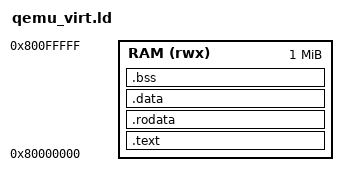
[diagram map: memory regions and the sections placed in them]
/* Linker script of programs for QEMU virt machine: RAM at 0x80000000,
 * QEMU starts at the beginning of RAM, so .text.start (_start of crt0.S) is first.
 */
OUTPUT_ARCH(riscv)
ENTRY(_start)

MEMORY
{
    RAM (rwx) : ORIGIN = 0x80000000, LENGTH = 1M
}

SECTIONS
{
    .text : {
        KEEP(*(.text.start))
        *(.text .text.*)
    } > RAM

    .rodata : {
        *(.rodata .rodata.* .srodata .srodata.*)
    } > RAM

    .data : {
        *(.data .data.*)
        __global_pointer$ = . + 0x800;
        *(.sdata .sdata.*)
    } > RAM

    .bss (NOLOAD) : ALIGN(4) {
        __bss_start = .;
        *(.sbss .sbss.* .bss .bss.* COMMON)
        . = ALIGN(4);
        __bss_end = .;
    } > RAM

    __stack_top = ORIGIN(RAM) + LENGTH(RAM);
}
